# f28e12x_gpio_data_regs register map
Vendor: Texas Instruments
Peripheral module from a debugger description file (folder C2000).
Address unit: 16 bits
Registers are 32-bit, read-write, no defined reset value unless marked. A register's access mark holds for its fields unless they carry their own. Offsets are as the file gives them; lines under a group give offsets from that group; [hi:lo] are bit positions; {n}, {i} and the like mark numbered series; 'fields as' and 'values as' point back to an identical list; <NAME> marks a mode.

## GPIO_DATA_REGS — GPIO DATA Registers
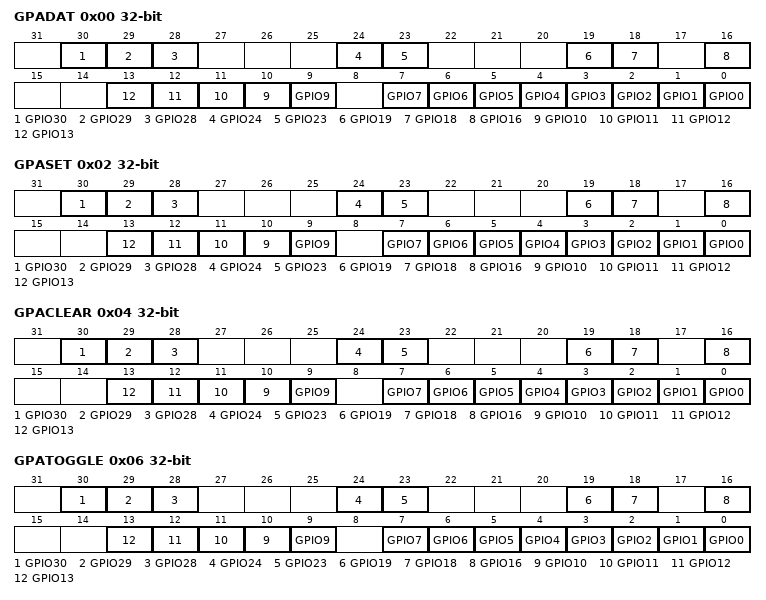
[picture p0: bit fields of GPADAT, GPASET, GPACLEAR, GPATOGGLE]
0x00 GPADAT — GPIO A Data Register (GPIO0 to 31)
  [30] GPIO30 — Data Register for this pin
  [29] GPIO29 — Data Register for this pin
  [28] GPIO28 — Data Register for this pin
  [24] GPIO24 — Data Register for this pin
  [23] GPIO23 — Data Register for this pin
  [19] GPIO19 — Data Register for this pin
  [18] GPIO18 — Data Register for this pin
  [16] GPIO16 — Data Register for this pin
  [n] GPIO{n} (n=9..13) — Data Register for this pin
  [n] GPIO{n} (n=0..7) — Data Register for this pin
0x02 GPASET — GPIO A Data Set Register (GPIO0 to 31)
  [30] GPIO30 — Output Set bit for this pin
  [29] GPIO29 — Output Set bit for this pin
  [28] GPIO28 — Output Set bit for this pin
  [24] GPIO24 — Output Set bit for this pin
  [23] GPIO23 — Output Set bit for this pin
  [19] GPIO19 — Output Set bit for this pin
  [18] GPIO18 — Output Set bit for this pin
  [16] GPIO16 — Output Set bit for this pin
  [n] GPIO{n} (n=9..13) — Output Set bit for this pin
  [n] GPIO{n} (n=0..7) — Output Set bit for this pin
0x04 GPACLEAR — GPIO A Data Clear Register (GPIO0 to 31)
  [30] GPIO30 — Output Clear bit for this pin
  [29] GPIO29 — Output Clear bit for this pin
  [28] GPIO28 — Output Clear bit for this pin
  [24] GPIO24 — Output Clear bit for this pin
  [23] GPIO23 — Output Clear bit for this pin
  [19] GPIO19 — Output Clear bit for this pin
  [18] GPIO18 — Output Clear bit for this pin
  [16] GPIO16 — Output Clear bit for this pin
  [n] GPIO{n} (n=9..13) — Output Clear bit for this pin
  [n] GPIO{n} (n=0..7) — Output Clear bit for this pin
0x06 GPATOGGLE — GPIO A Data Toggle Register (GPIO0 to 31)
  [30] GPIO30 — Output Toggle bit for this pin
  [29] GPIO29 — Output Toggle bit for this pin
  [28] GPIO28 — Output Toggle bit for this pin
  [24] GPIO24 — Output Toggle bit for this pin
  [23] GPIO23 — Output Toggle bit for this pin
  [19] GPIO19 — Output Toggle bit for this pin
  [18] GPIO18 — Output Toggle bit for this pin
  [16] GPIO16 — Output Toggle bit for this pin
  [n] GPIO{n} (n=9..13) — Output Toggle bit for this pin
  [n] GPIO{n} (n=0..7) — Output Toggle bit for this pin
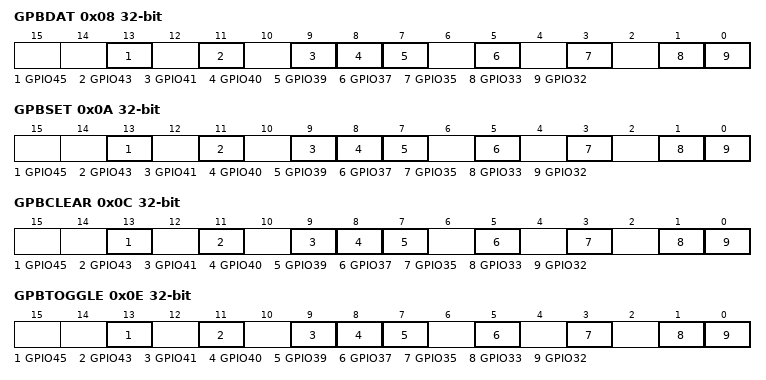
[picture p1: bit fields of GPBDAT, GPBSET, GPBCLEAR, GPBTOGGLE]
0x08 GPBDAT — GPIO B Data Register (GPIO32 to 63)
  [13] GPIO45 — Data Register for this pin
  [11] GPIO43 — Data Register for this pin
  [9] GPIO41 — Data Register for this pin
  [8] GPIO40 — Data Register for this pin
  [7] GPIO39 — Data Register for this pin
  [5] GPIO37 — Data Register for this pin
  [3] GPIO35 — Data Register for this pin
  [1] GPIO33 — Data Register for this pin
  [0] GPIO32 — Data Register for this pin
0x0A GPBSET — GPIO B Data Set Register (GPIO32 to 63)
  [13] GPIO45 — Output Set bit for this pin
  [11] GPIO43 — Output Set bit for this pin
  [9] GPIO41 — Output Set bit for this pin
  [8] GPIO40 — Output Set bit for this pin
  [7] GPIO39 — Output Set bit for this pin
  [5] GPIO37 — Output Set bit for this pin
  [3] GPIO35 — Output Set bit for this pin
  [1] GPIO33 — Output Set bit for this pin
  [0] GPIO32 — Output Set bit for this pin
0x0C GPBCLEAR — GPIO B Data Clear Register (GPIO32 to 63)
  [13] GPIO45 — Output Clear bit for this pin
  [11] GPIO43 — Output Clear bit for this pin
  [9] GPIO41 — Output Clear bit for this pin
  [8] GPIO40 — Output Clear bit for this pin
  [7] GPIO39 — Output Clear bit for this pin
  [5] GPIO37 — Output Clear bit for this pin
  [3] GPIO35 — Output Clear bit for this pin
  [1] GPIO33 — Output Clear bit for this pin
  [0] GPIO32 — Output Clear bit for this pin
0x0E GPBTOGGLE — GPIO B Data Toggle Register (GPIO32 to 63)
  [13] GPIO45 — Output Toggle bit for this pin
  [11] GPIO43 — Output Toggle bit for this pin
  [9] GPIO41 — Output Toggle bit for this pin
  [8] GPIO40 — Output Toggle bit for this pin
  [7] GPIO39 — Output Toggle bit for this pin
  [5] GPIO37 — Output Toggle bit for this pin
  [3] GPIO35 — Output Toggle bit for this pin
  [1] GPIO33 — Output Toggle bit for this pin
  [0] GPIO32 — Output Toggle bit for this pin
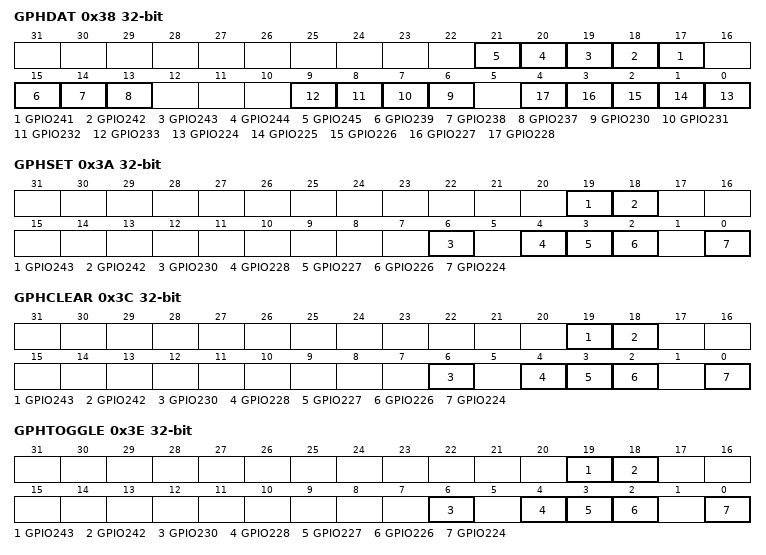
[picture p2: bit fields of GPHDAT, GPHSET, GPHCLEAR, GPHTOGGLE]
0x38 GPHDAT — GPIO H Data Register (GPIO224 to 255)
  [n-224] GPIO{n} (n=241..245) — Data Register for this pin
  [15] GPIO239 — Data Register for this pin
  [14] GPIO238 — Data Register for this pin
  [13] GPIO237 — Data Register for this pin
  [n-224] GPIO{n} (n=230..233) — Data Register for this pin
  [n-224] GPIO{n} (n=224..228) — Data Register for this pin
0x3A GPHSET — GPIO H Data Set Register (GPIO224 to 255)
  [19] GPIO243 — Output Set bit for this pin
  [18] GPIO242 — Output Set bit for this pin
  [6] GPIO230 — Output Set bit for this pin
  [4] GPIO228 — Output Set bit for this pin
  [3] GPIO227 — Output Set bit for this pin
  [2] GPIO226 — Output Set bit for this pin
  [0] GPIO224 — Output Set bit for this pin
0x3C GPHCLEAR — GPIO H Data Clear Register (GPIO224 to 255)
  [19] GPIO243 — Output Clear bit for this pin
  [18] GPIO242 — Output Clear bit for this pin
  [6] GPIO230 — Output Clear bit for this pin
  [4] GPIO228 — Output Clear bit for this pin
  [3] GPIO227 — Output Clear bit for this pin
  [2] GPIO226 — Output Clear bit for this pin
  [0] GPIO224 — Output Clear bit for this pin
0x3E GPHTOGGLE — GPIO H Data Toggle Register (GPIO224 to 255)
  [19] GPIO243 — Output Toggle bit for this pin
  [18] GPIO242 — Output Toggle bit for this pin
  [6] GPIO230 — Output Toggle bit for this pin
  [4] GPIO228 — Output Toggle bit for this pin
  [3] GPIO227 — Output Toggle bit for this pin
  [2] GPIO226 — Output Toggle bit for this pin
  [0] GPIO224 — Output Toggle bit for this pin
